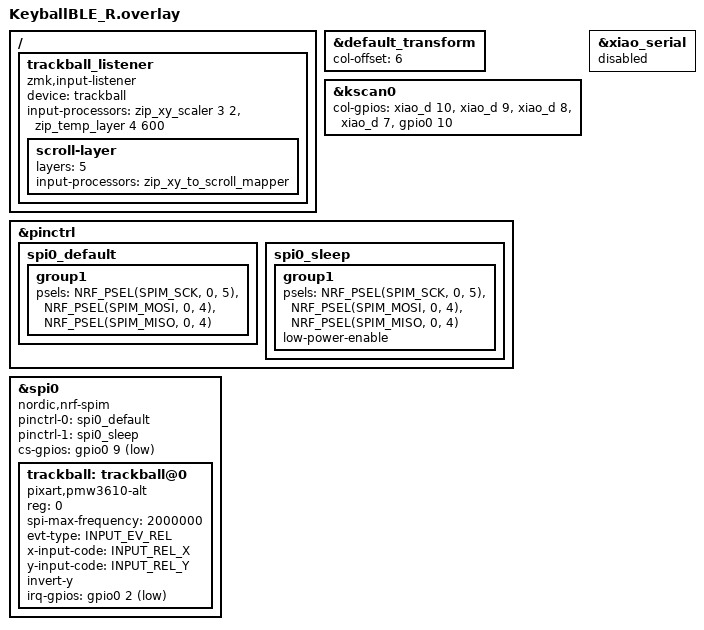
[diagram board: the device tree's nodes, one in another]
/*
 * Copyright (c) 2020 ZMK Contributors
 *
 * SPDX-License-Identifier: MIT
 */
#include <dt-bindings/input/input-event-codes.h>
#include <dt-bindings/zmk/matrix_transform.h>
#include <input/processors.dtsi>
#include "KeyballBLE.dtsi"

&default_transform {
    col-offset = <6>;
};

&kscan0 {
    col-gpios
        = <&xiao_d 10 GPIO_ACTIVE_HIGH>
        , <&xiao_d 9 GPIO_ACTIVE_HIGH>
        , <&xiao_d 8 GPIO_ACTIVE_HIGH>
        , <&xiao_d 7 GPIO_ACTIVE_HIGH>
        , <&gpio0 10 GPIO_ACTIVE_HIGH>
        ;
};

/ {
    trackball_listener: trackball_listener {
        compatible = "zmk,input-listener";
        device = <&trackball>;
        input-processors
                    /* 1. 感度調節 (zip_xy_scaler 分子 分母) */
                    /* 例: <&zip_xy_scaler 2 1> (2倍速), <&zip_xy_scaler 1 2> (半分) */
                    /* 現在: 等倍 (1/1) */
                    = <&zip_xy_scaler 3 2>

                    /* 2. オートマウスレイヤー (zip_temp_layer レイヤー番号 タイムアウトms) */
                    /* トラックボールを動かすと レイヤー4 (MOUSE) に切り替わり、 */
                    /* 600ms 操作しないと戻ります */
                    , <&zip_temp_layer 4 600>;

        /* レイヤー5 (SCROLL) の時の動作 */
        scroll-layer {
            layers = <5>;
            input-processors = <&zip_xy_to_scroll_mapper>;
        };
    };
};

&pinctrl {
    spi0_default: spi0_default {
        group1 {
            psels = <NRF_PSEL(SPIM_SCK, 0, 5)>,    // D5 = P0.05
                    <NRF_PSEL(SPIM_MOSI, 0, 4)>,   // D4 = P0.04
                    <NRF_PSEL(SPIM_MISO, 0, 4)>;
                    //<NRF_PSEL(SPIM_MISO, 0, 3)>;   // D3 = P0.03 (推定) 動かなかった
                    //<NRF_PSEL(SPIM_MISO, 1, 11)>;  // D3 = P1.11　動かなかった
        };
    };

    spi0_sleep: spi0_sleep {
        group1 {
            psels = <NRF_PSEL(SPIM_SCK, 0, 5)>,
                    <NRF_PSEL(SPIM_MOSI, 0, 4)>,
                    <NRF_PSEL(SPIM_MISO, 0, 4)>;
                     // <NRF_PSEL(SPIM_MISO, 0, 3)>;
                     // <<NRF_PSEL(SPIM_MISO, 1, 11)>;
            low-power-enable;
        };
    };
};

&xiao_serial { status = "disabled"; };

&spi0 {
    status = "okay";
    compatible = "nordic,nrf-spim";
    pinctrl-0 = <&spi0_default>;
    pinctrl-1 = <&spi0_sleep>;
    pinctrl-names = "default", "sleep";
    cs-gpios = <&gpio0 9 GPIO_ACTIVE_LOW>;  // D9 = P0.09
    //cs-gpios = <&gpio0 10 GPIO_ACTIVE_LOW>;  // D9 = P0.10
    trackball: trackball@0 {
        status = "okay";
        //compatible = "pixart,pmw3610";//ビルドエラーになる。
        compatible = "pixart,pmw3610-alt";
        reg = <0>;
        spi-max-frequency = <2000000>;

        evt-type = <INPUT_EV_REL>;
        x-input-code = <INPUT_REL_X>;
        y-input-code = <INPUT_REL_Y>;
        invert-y;
        irq-gpios = <&gpio0 2 (GPIO_ACTIVE_LOW | GPIO_PULL_UP)>;  // D2 = P0.02
        //irq-gpios = <&gpio0 9 (GPIO_ACTIVE_LOW | GPIO_PULL_UP)>;  // D2 = P0.09
        //automouse-layer = <4>;
        //scroll-layers = <5>;
    };
};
